AUTOSAR XML (schema 00051)
package /Components
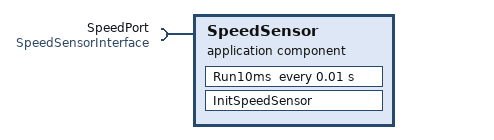
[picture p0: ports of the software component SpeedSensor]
  application sw component type SpeedSensor
    require port SpeedPort: required-interface=SpeedSensorInterface
    behavior SpeedSensor_IB
      timing event TE_Run10ms: start-on-event=Run10ms, period=0.01
      init event IE_InitSpeedSensor: start-on-event=InitSpeedSensor
      runnable Run10ms
        data-read-access:
          access VA_Run10ms_SpeedPort: accessed-variable=SpeedPort.VehicleSpeed
      runnable InitSpeedSensor
